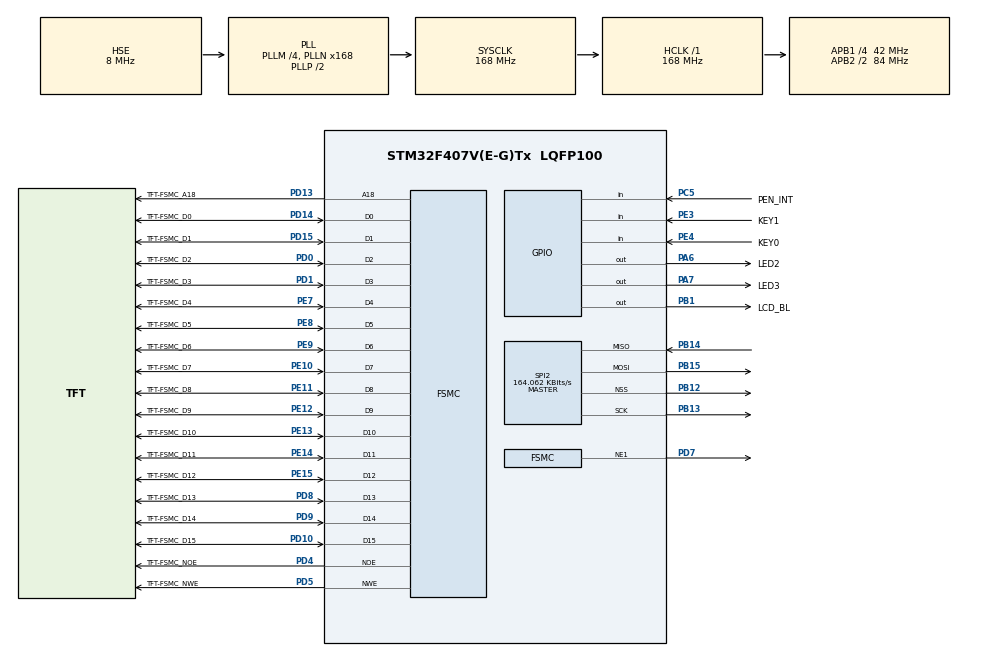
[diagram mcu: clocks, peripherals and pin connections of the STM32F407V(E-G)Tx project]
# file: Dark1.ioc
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FREERTOS.Tasks01=defaultTask,24,128,StartDefaultTask,Default,NULL,Dynamic,NULL,NULL;blinkTask,8,128,StartBlinkTask,Default,NULL,Dynamic,NULL,NULL
Mcu.Family=STM32F4
Mcu.Name=STM32F407V(E-G)Tx
Mcu.Package=LQFP100
NVIC.PriorityGroup=NVIC_PRIORITYGROUP_4
NVIC.TIM8_UP_TIM13_IRQn=true\:0\:0\:false\:false\:true\:false\:false\:true
NVIC.TimeBase=TIM8_UP_TIM13_IRQn
NVIC.TimeBaseIP=TIM13
PA11.Signal=USB_OTG_FS_DM
PA12.Signal=USB_OTG_FS_DP
PA13.GPIO_Label=JTAG-TMS
PA13.Mode=JTAG_5_pins
PA13.Signal=SYS_JTMS-SWDIO
PA14.GPIO_Label=JTAG-TCK
PA14.Mode=JTAG_5_pins
PA14.Signal=SYS_JTCK-SWCLK
PA15.GPIO_Label=JTAG-TDI
PA15.Mode=JTAG_5_pins
PA15.Signal=SYS_JTDI
PA6.GPIO_Label=LED2
PA6.PinState=GPIO_PIN_SET
PA6.Signal=GPIO_Output
PA7.GPIO_Label=LED3
PA7.PinState=GPIO_PIN_SET
PA7.Signal=GPIO_Output
PB1.GPIO_Label=LCD_BL
PB1.PinState=GPIO_PIN_SET
PB1.Signal=GPIO_Output
PB12.Mode=NSS_Signal_Hard_Output
PB12.Signal=SPI2_NSS
PB13.Mode=Full_Duplex_Master
PB13.Signal=SPI2_SCK
PB14.Mode=Full_Duplex_Master
PB14.Signal=SPI2_MISO
PB15.Mode=Full_Duplex_Master
PB15.Signal=SPI2_MOSI
PB3.GPIO_Label=JTAG-TDO
PB3.Mode=JTAG_5_pins
PB3.Signal=SYS_JTDO-SWO
PB4.GPIO_Label=JTAG-TRST
PB4.Mode=JTAG_5_pins
PB4.Signal=SYS_JTRST
PB5.Signal=SPI1_MOSI
PC10.Signal=SDIO_D2
PC11.Signal=SDIO_D3
PC12.Signal=SDIO_CK
PC14-OSC32_IN.Mode=LSE-External-Oscillator
PC14-OSC32_IN.Signal=RCC_OSC32_IN
PC15-OSC32_OUT.Mode=LSE-External-Oscillator
PC15-OSC32_OUT.Signal=RCC_OSC32_OUT
PC5.GPIO_Label=PEN_INT
PC5.GPIO_PuPd=GPIO_PULLUP
PC5.Signal=GPIO_Input
PC8.Signal=SDIO_D0
PC9.Signal=SDIO_D1
PD0.GPIO_Label=TFT-FSMC_D2
PD0.Mode=16b-d1
PD0.Signal=FSMC_D2
PD1.GPIO_Label=TFT-FSMC_D3
PD1.Mode=16b-d1
PD1.Signal=FSMC_D3
PD10.GPIO_Label=TFT-FSMC_D15
PD10.Mode=16b-d1
PD10.Signal=FSMC_D15
PD13.GPIO_Label=TFT-FSMC_A18
PD13.Mode=A18_1
PD13.Signal=FSMC_A18
PD14.GPIO_Label=TFT-FSMC_D0
PD14.Mode=16b-d1
PD14.Signal=FSMC_D0
PD15.GPIO_Label=TFT-FSMC_D1
PD15.Mode=16b-d1
PD15.Signal=FSMC_D1
PD2.Signal=SDIO_CMD
PD4.GPIO_Label=TFT-FSMC_NOE
PD4.Mode=Lcd1
PD4.Signal=FSMC_NOE
PD5.GPIO_Label=TFT-FSMC_NWE
PD5.Mode=Lcd1
PD5.Signal=FSMC_NWE
PD7.Mode=NorPsramChipSelect1_1
PD7.Signal=FSMC_NE1
PD8.GPIO_Label=TFT-FSMC_D13
PD8.Mode=16b-d1
PD8.Signal=FSMC_D13
PD9.GPIO_Label=TFT-FSMC_D14
PD9.Mode=16b-d1
PD9.Signal=FSMC_D14
PE10.GPIO_Label=TFT-FSMC_D7
PE10.Mode=16b-d1
PE10.Signal=FSMC_D7
PE11.GPIO_Label=TFT-FSMC_D8
PE11.Mode=16b-d1
PE11.Signal=FSMC_D8
PE12.GPIO_Label=TFT-FSMC_D9
PE12.Mode=16b-d1
PE12.Signal=FSMC_D9
PE13.GPIO_Label=TFT-FSMC_D10
PE13.Mode=16b-d1
PE13.Signal=FSMC_D10
PE14.GPIO_Label=TFT-FSMC_D11
PE14.Mode=16b-d1
PE14.Signal=FSMC_D11
PE15.GPIO_Label=TFT-FSMC_D12
PE15.Mode=16b-d1
PE15.Signal=FSMC_D12
PE3.GPIO_Label=KEY1
PE3.GPIO_PuPd=GPIO_PULLUP
PE3.Signal=GPIO_Input
PE4.GPIO_Label=KEY0
PE4.GPIO_PuPd=GPIO_PULLUP
PE4.Signal=GPIO_Input
PE7.GPIO_Label=TFT-FSMC_D4
PE7.Mode=16b-d1
PE7.Signal=FSMC_D4
PE8.GPIO_Label=TFT-FSMC_D5
PE8.Mode=16b-d1
PE8.Signal=FSMC_D5
PE9.GPIO_Label=TFT-FSMC_D6
PE9.Mode=16b-d1
PE9.Signal=FSMC_D6
PH0-OSC_IN.Mode=HSE-External-Oscillator
PH0-OSC_IN.Signal=RCC_OSC_IN
PH1-OSC_OUT.Mode=HSE-External-Oscillator
PH1-OSC_OUT.Signal=RCC_OSC_OUT
ProjectManager.HeapSize=0x200
ProjectManager.StackSize=0x400
ProjectManager.TargetToolchain=STM32CubeIDE
RCC.48MHZClocksFreq_Value=48000000
RCC.AHBFreq_Value=168000000
RCC.APB1CLKDivider=RCC_HCLK_DIV4
RCC.APB1Freq_Value=42000000
RCC.APB1TimFreq_Value=84000000
RCC.APB2CLKDivider=RCC_HCLK_DIV2
RCC.APB2Freq_Value=84000000
RCC.APB2TimFreq_Value=168000000
RCC.CortexFreq_Value=168000000
RCC.HCLKFreq_Value=168000000
RCC.HSE_VALUE=8000000
RCC.HSI_VALUE=16000000
RCC.PLLM=4
RCC.PLLN=168
RCC.PLLQ=7
RCC.PLLSourceVirtual=RCC_PLLSOURCE_HSE
RCC.RCC_RTC_Clock_Source=RCC_RTCCLKSOURCE_LSE
RCC.RCC_RTC_Clock_SourceVirtual=RCC_RTCCLKSOURCE_LSE
RCC.SYSCLKFreq_VALUE=168000000
RCC.SYSCLKSource=RCC_SYSCLKSOURCE_PLLCLK
RCC.VCOOutputFreq_Value=336000000
SPI2.BaudRatePrescaler=SPI_BAUDRATEPRESCALER_256
SPI2.CalculateBaudRate=164.062 KBits/s
SPI2.Direction=SPI_DIRECTION_2LINES
SPI2.Mode=SPI_MODE_MASTER
SPI2.VirtualNSS=VM_NSSHARD
SPI2.VirtualType=VM_MASTER
VP_FREERTOS_VS_CMSIS_V2.Mode=CMSIS_V2
VP_RTC_VS_RTC_Activate.Mode=RTC_Enabled
VP_SYS_VS_tim13.Mode=TIM13
VP_TIM1_VS_ClockSourceINT.Mode=Internal
VP_TIM1_VS_ClockSourceITR.Mode=TriggerSource_ITR0
board=custom

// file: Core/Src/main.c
/* USER CODE BEGIN Header */
/**
  ******************************************************************************
  * @file           : main.c
  * @brief          : Main program body
  ******************************************************************************
  * @attention
  *
  * <h2><center>&copy; Copyright (c) 2020 STMicroelectronics.
  * All rights reserved.</center></h2>
  *
  * This software component is licensed by ST under BSD 3-Clause license,
  * the "License"; You may not use this file except in compliance with the
  * License. You may obtain a copy of the License at:
  *                        opensource.org/licenses/BSD-3-Clause
  *
  ******************************************************************************
  */
/* USER CODE END Header */
#include "main.h"
#include "cmsis_os.h"

/* USER CODE BEGIN Includes */
#include "board.h"
#include "app.hpp"
/* USER CODE END Includes */

RTC_HandleTypeDef hrtc;

SPI_HandleTypeDef hspi2;

TIM_HandleTypeDef htim1;

SRAM_HandleTypeDef hsram1;

/* Definitions for defaultTask */
osThreadId_t defaultTaskHandle;
const osThreadAttr_t defaultTask_attributes = {
  .name = "defaultTask",
  .priority = (osPriority_t) osPriorityNormal,
  .stack_size = 128 * 4
};
/* Definitions for blinkTask */
osThreadId_t blinkTaskHandle;
const osThreadAttr_t blinkTask_attributes = {
  .name = "blinkTask",
  .priority = (osPriority_t) osPriorityLow,
  .stack_size = 128 * 4
};

void SystemClock_Config(void);
static void MX_GPIO_Init(void);
static void MX_TIM1_Init(void);
static void MX_RTC_Init(void);
static void MX_SPI2_Init(void);
static void MX_FSMC_Init(void);
void StartDefaultTask(void *argument);
void StartBlinkTask(void *argument);

int main(void)
{

  /* MCU Configuration--------------------------------------------------------*/

  /* Reset of all peripherals, Initializes the Flash interface and the Systick. */
  HAL_Init();

  /* Configure the system clock */
  SystemClock_Config();

  /* Initialize all configured peripherals */
  MX_GPIO_Init();
  MX_TIM1_Init();
  MX_RTC_Init();
  MX_SPI2_Init();
  MX_FSMC_Init();
  /* USER CODE BEGIN 2 */

  AppInit();
  /* USER CODE END 2 */

  /* Init scheduler */
  osKernelInitialize();

  /* Create the thread(s) */
  /* creation of defaultTask */
  defaultTaskHandle = osThreadNew(StartDefaultTask, NULL, &defaultTask_attributes);

  /* creation of blinkTask */
  blinkTaskHandle = osThreadNew(StartBlinkTask, NULL, &blinkTask_attributes);

  /* Start scheduler */
  osKernelStart();

  /* We should never get here as control is now taken by the scheduler */
  /* Infinite loop */
  while (1)
  {

  }
}

void SystemClock_Config(void)
{
  RCC_OscInitTypeDef RCC_OscInitStruct = {0};
  RCC_ClkInitTypeDef RCC_ClkInitStruct = {0};
  RCC_PeriphCLKInitTypeDef PeriphClkInitStruct = {0};

  /** Configure the main internal regulator output voltage
  */
  __HAL_RCC_PWR_CLK_ENABLE();
  __HAL_PWR_VOLTAGESCALING_CONFIG(PWR_REGULATOR_VOLTAGE_SCALE1);
  /** Initializes the RCC Oscillators according to the specified parameters
  * in the RCC_OscInitTypeDef structure.
  */
  RCC_OscInitStruct.OscillatorType = RCC_OSCILLATORTYPE_HSE|RCC_OSCILLATORTYPE_LSE;
  RCC_OscInitStruct.HSEState = RCC_HSE_ON;
  RCC_OscInitStruct.LSEState = RCC_LSE_ON;
  RCC_OscInitStruct.PLL.PLLState = RCC_PLL_ON;
  RCC_OscInitStruct.PLL.PLLSource = RCC_PLLSOURCE_HSE;
  RCC_OscInitStruct.PLL.PLLM = 4;
  RCC_OscInitStruct.PLL.PLLN = 168;
  RCC_OscInitStruct.PLL.PLLP = RCC_PLLP_DIV2;
  RCC_OscInitStruct.PLL.PLLQ = 7;
  if (HAL_RCC_OscConfig(&RCC_OscInitStruct) != HAL_OK)
  {
    Error_Handler();
  }
  /** Initializes the CPU, AHB and APB buses clocks
  */
  RCC_ClkInitStruct.ClockType = RCC_CLOCKTYPE_HCLK|RCC_CLOCKTYPE_SYSCLK
                              |RCC_CLOCKTYPE_PCLK1|RCC_CLOCKTYPE_PCLK2;
  RCC_ClkInitStruct.SYSCLKSource = RCC_SYSCLKSOURCE_PLLCLK;
  RCC_ClkInitStruct.AHBCLKDivider = RCC_SYSCLK_DIV1;
  RCC_ClkInitStruct.APB1CLKDivider = RCC_HCLK_DIV4;
  RCC_ClkInitStruct.APB2CLKDivider = RCC_HCLK_DIV2;

  if (HAL_RCC_ClockConfig(&RCC_ClkInitStruct, FLASH_LATENCY_5) != HAL_OK)
  {
    Error_Handler();
  }
  PeriphClkInitStruct.PeriphClockSelection = RCC_PERIPHCLK_RTC;
  PeriphClkInitStruct.RTCClockSelection = RCC_RTCCLKSOURCE_LSE;
  if (HAL_RCCEx_PeriphCLKConfig(&PeriphClkInitStruct) != HAL_OK)
  {
    Error_Handler();
  }
}

static void MX_RTC_Init(void)
{

  /** Initialize RTC Only
  */
  hrtc.Instance = RTC;
  hrtc.Init.HourFormat = RTC_HOURFORMAT_24;
  hrtc.Init.AsynchPrediv = 127;
  hrtc.Init.SynchPrediv = 255;
  hrtc.Init.OutPut = RTC_OUTPUT_DISABLE;
  hrtc.Init.OutPutPolarity = RTC_OUTPUT_POLARITY_HIGH;
  hrtc.Init.OutPutType = RTC_OUTPUT_TYPE_OPENDRAIN;
  if (HAL_RTC_Init(&hrtc) != HAL_OK)
  {
    Error_Handler();
  }

}

static void MX_SPI2_Init(void)
{

  /* SPI2 parameter configuration*/
  hspi2.Instance = SPI2;
  hspi2.Init.Mode = SPI_MODE_MASTER;
  hspi2.Init.Direction = SPI_DIRECTION_2LINES;
  hspi2.Init.DataSize = SPI_DATASIZE_8BIT;
  hspi2.Init.CLKPolarity = SPI_POLARITY_LOW;
  hspi2.Init.CLKPhase = SPI_PHASE_1EDGE;
  hspi2.Init.NSS = SPI_NSS_HARD_OUTPUT;
  hspi2.Init.BaudRatePrescaler = SPI_BAUDRATEPRESCALER_256;
  hspi2.Init.FirstBit = SPI_FIRSTBIT_MSB;
  hspi2.Init.TIMode = SPI_TIMODE_DISABLE;
  hspi2.Init.CRCCalculation = SPI_CRCCALCULATION_DISABLE;
  hspi2.Init.CRCPolynomial = 10;
  if (HAL_SPI_Init(&hspi2) != HAL_OK)
  {
    Error_Handler();
  }

}

static void MX_TIM1_Init(void)
{

  TIM_ClockConfigTypeDef sClockSourceConfig = {0};
  TIM_SlaveConfigTypeDef sSlaveConfig = {0};
  TIM_MasterConfigTypeDef sMasterConfig = {0};

  htim1.Instance = TIM1;
  htim1.Init.Prescaler = 0;
  htim1.Init.CounterMode = TIM_COUNTERMODE_UP;
  htim1.Init.Period = 65535;
  htim1.Init.ClockDivision = TIM_CLOCKDIVISION_DIV1;
  htim1.Init.RepetitionCounter = 0;
  htim1.Init.AutoReloadPreload = TIM_AUTORELOAD_PRELOAD_DISABLE;
  if (HAL_TIM_Base_Init(&htim1) != HAL_OK)
  {
    Error_Handler();
  }
  sClockSourceConfig.ClockSource = TIM_CLOCKSOURCE_INTERNAL;
  if (HAL_TIM_ConfigClockSource(&htim1, &sClockSourceConfig) != HAL_OK)
  {
    Error_Handler();
  }
  sSlaveConfig.SlaveMode = TIM_SLAVEMODE_DISABLE;
  sSlaveConfig.InputTrigger = TIM_TS_ITR0;
  if (HAL_TIM_SlaveConfigSynchro(&htim1, &sSlaveConfig) != HAL_OK)
  {
    Error_Handler();
  }
  sMasterConfig.MasterOutputTrigger = TIM_TRGO_RESET;
  sMasterConfig.MasterSlaveMode = TIM_MASTERSLAVEMODE_DISABLE;
  if (HAL_TIMEx_MasterConfigSynchronization(&htim1, &sMasterConfig) != HAL_OK)
  {
    Error_Handler();
  }

}

static void MX_GPIO_Init(void)
{
  GPIO_InitTypeDef GPIO_InitStruct = {0};

  /* GPIO Ports Clock Enable */
  __HAL_RCC_GPIOE_CLK_ENABLE();
  __HAL_RCC_GPIOC_CLK_ENABLE();
  __HAL_RCC_GPIOH_CLK_ENABLE();
  __HAL_RCC_GPIOA_CLK_ENABLE();
  __HAL_RCC_GPIOB_CLK_ENABLE();
  __HAL_RCC_GPIOD_CLK_ENABLE();

  /*Configure GPIO pin Output Level */
  HAL_GPIO_WritePin(GPIOA, LED2_Pin|LED3_Pin, GPIO_PIN_SET);

  /*Configure GPIO pin Output Level */
  HAL_GPIO_WritePin(LCD_BL_GPIO_Port, LCD_BL_Pin, GPIO_PIN_SET);

  /*Configure GPIO pins : KEY1_Pin KEY0_Pin */
  GPIO_InitStruct.Pin = KEY1_Pin|KEY0_Pin;
  GPIO_InitStruct.Mode = GPIO_MODE_INPUT;
  GPIO_InitStruct.Pull = GPIO_PULLUP;
  HAL_GPIO_Init(GPIOE, &GPIO_InitStruct);

  /*Configure GPIO pins : LED2_Pin LED3_Pin */
  GPIO_InitStruct.Pin = LED2_Pin|LED3_Pin;
  GPIO_InitStruct.Mode = GPIO_MODE_OUTPUT_PP;
  GPIO_InitStruct.Pull = GPIO_NOPULL;
  GPIO_InitStruct.Speed = GPIO_SPEED_FREQ_LOW;
  HAL_GPIO_Init(GPIOA, &GPIO_InitStruct);

  /*Configure GPIO pin : PEN_INT_Pin */
  GPIO_InitStruct.Pin = PEN_INT_Pin;
  GPIO_InitStruct.Mode = GPIO_MODE_INPUT;
  GPIO_InitStruct.Pull = GPIO_PULLUP;
  HAL_GPIO_Init(PEN_INT_GPIO_Port, &GPIO_InitStruct);

  /*Configure GPIO pin : LCD_BL_Pin */
  GPIO_InitStruct.Pin = LCD_BL_Pin;
  GPIO_InitStruct.Mode = GPIO_MODE_OUTPUT_PP;
  GPIO_InitStruct.Pull = GPIO_NOPULL;
  GPIO_InitStruct.Speed = GPIO_SPEED_FREQ_LOW;
  HAL_GPIO_Init(LCD_BL_GPIO_Port, &GPIO_InitStruct);

  /*Configure GPIO pins : PC8 PC9 PC10 PC11
                           PC12 */
  GPIO_InitStruct.Pin = GPIO_PIN_8|GPIO_PIN_9|GPIO_PIN_10|GPIO_PIN_11
                          |GPIO_PIN_12;
  GPIO_InitStruct.Mode = GPIO_MODE_AF_PP;
  GPIO_InitStruct.Pull = GPIO_NOPULL;
  GPIO_InitStruct.Speed = GPIO_SPEED_FREQ_VERY_HIGH;
  GPIO_InitStruct.Alternate = GPIO_AF12_SDIO;
  HAL_GPIO_Init(GPIOC, &GPIO_InitStruct);

  /*Configure GPIO pins : PA11 PA12 */
  GPIO_InitStruct.Pin = GPIO_PIN_11|GPIO_PIN_12;
  GPIO_InitStruct.Mode = GPIO_MODE_AF_PP;
  GPIO_InitStruct.Pull = GPIO_NOPULL;
  GPIO_InitStruct.Speed = GPIO_SPEED_FREQ_VERY_HIGH;
  GPIO_InitStruct.Alternate = GPIO_AF10_OTG_FS;
  HAL_GPIO_Init(GPIOA, &GPIO_InitStruct);

  /*Configure GPIO pin : PD2 */
  GPIO_InitStruct.Pin = GPIO_PIN_2;
  GPIO_InitStruct.Mode = GPIO_MODE_AF_PP;
  GPIO_InitStruct.Pull = GPIO_NOPULL;
  GPIO_InitStruct.Speed = GPIO_SPEED_FREQ_VERY_HIGH;
  GPIO_InitStruct.Alternate = GPIO_AF12_SDIO;
  HAL_GPIO_Init(GPIOD, &GPIO_InitStruct);

  /*Configure GPIO pin : PB5 */
  GPIO_InitStruct.Pin = GPIO_PIN_5;
  GPIO_InitStruct.Mode = GPIO_MODE_AF_PP;
  GPIO_InitStruct.Pull = GPIO_NOPULL;
  GPIO_InitStruct.Speed = GPIO_SPEED_FREQ_VERY_HIGH;
  GPIO_InitStruct.Alternate = GPIO_AF5_SPI1;
  HAL_GPIO_Init(GPIOB, &GPIO_InitStruct);

}

/* FSMC initialization function */
static void MX_FSMC_Init(void)
{

  FSMC_NORSRAM_TimingTypeDef Timing = {0};

  /** Perform the SRAM1 memory initialization sequence
  */
  hsram1.Instance = FSMC_NORSRAM_DEVICE;
  hsram1.Extended = FSMC_NORSRAM_EXTENDED_DEVICE;
  /* hsram1.Init */
  hsram1.Init.NSBank = FSMC_NORSRAM_BANK1;
  hsram1.Init.DataAddressMux = FSMC_DATA_ADDRESS_MUX_DISABLE;
  hsram1.Init.MemoryType = FSMC_MEMORY_TYPE_SRAM;
  hsram1.Init.MemoryDataWidth = FSMC_NORSRAM_MEM_BUS_WIDTH_16;
  hsram1.Init.BurstAccessMode = FSMC_BURST_ACCESS_MODE_DISABLE;
  hsram1.Init.WaitSignalPolarity = FSMC_WAIT_SIGNAL_POLARITY_LOW;
  hsram1.Init.WrapMode = FSMC_WRAP_MODE_DISABLE;
  hsram1.Init.WaitSignalActive = FSMC_WAIT_TIMING_BEFORE_WS;
  hsram1.Init.WriteOperation = FSMC_WRITE_OPERATION_ENABLE;
  hsram1.Init.WaitSignal = FSMC_WAIT_SIGNAL_DISABLE;
  hsram1.Init.ExtendedMode = FSMC_EXTENDED_MODE_DISABLE;
  hsram1.Init.AsynchronousWait = FSMC_ASYNCHRONOUS_WAIT_DISABLE;
  hsram1.Init.WriteBurst = FSMC_WRITE_BURST_DISABLE;
  hsram1.Init.PageSize = FSMC_PAGE_SIZE_NONE;
  /* Timing */
  Timing.AddressSetupTime = 15;
  Timing.AddressHoldTime = 15;
  Timing.DataSetupTime = 255;
  Timing.BusTurnAroundDuration = 15;
  Timing.CLKDivision = 16;
  Timing.DataLatency = 17;
  Timing.AccessMode = FSMC_ACCESS_MODE_A;
  /* ExtTiming */

  if (HAL_SRAM_Init(&hsram1, &Timing, NULL) != HAL_OK)
  {
    Error_Handler( );
  }

}

void StartDefaultTask(void *argument)
{
  /* USER CODE BEGIN 5 */
  /* Infinite loop */
  for(;;)
  {
	  AppLoop();
  }
  /* USER CODE END 5 */
}

void StartBlinkTask(void *argument)
{
  /* USER CODE BEGIN StartBlinkTask */
  /* Infinite loop */
  for(;;)
  {
	  LedToggle(LED2);
	  osDelay(50);
	  LedToggle(LED2);
	  osDelay(950);
  }
  /* USER CODE END StartBlinkTask */
}

 /**
  * @brief  Period elapsed callback in non blocking mode
  * @note   This function is called  when TIM13 interrupt took place, inside
  * HAL_TIM_IRQHandler(). It makes a direct call to HAL_IncTick() to increment
  * a global variable "uwTick" used as application time base.
  * @param  htim : TIM handle
  * @retval None
  */
void HAL_TIM_PeriodElapsedCallback(TIM_HandleTypeDef *htim)
{
  if (htim->Instance == TIM13) {
    HAL_IncTick();
  }
}

void Error_Handler(void)
{
  __disable_irq();
  while (1)
  {
  }
}

/************************ (C) COPYRIGHT STMicroelectronics *****END OF FILE****/
